# TC37XPD register map
Vendor: Infineon; Series: ATVMC; File version: 100
CPU: other r0p0, little endian, MPU, FPU, vendor SysTick, 4 interrupt priority bits
Registers are 32-bit, read-write, reset 0x0 unless marked. A register's access mark holds for its fields unless they carry their own. Offsets are from the block's base; [hi:lo] are bit positions; {n}, {i} and the like mark numbered series; 'fields as' and 'values as' point back to an identical list.

## ERAY0 (part 1 of 3) — ERAY
Base 0xF001C000
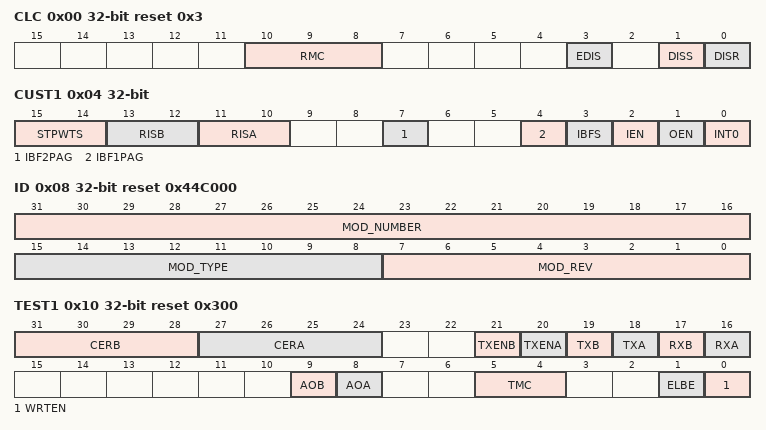
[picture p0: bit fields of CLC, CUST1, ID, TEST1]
0x00 CLC access per field reset 0x3 — Clock Control Register resetvalue={Application Reset:0x3}
  [10:8] RMC rw — Clock Divider in Run Mode RMC. This bit field is not affected by an application reset. This bit field only controls the kernel clock f CLC ERAY and not the sampling clock f SCLK .
  [3] EDIS rw — External Sleep Mode Request Disable Bit EDIS. Used to control module 8217 s sleep mode. If this bit is cleared the kernel clock f CLC ERAY and the sampling clock f SCLK are disabled during System Sleep Mode.
  [1] DISS ro — Module Disable Status Bit DISS. Bit indicates the current status of the module.
  [0] DISR rw — Module Disable Request Bit DISR. Used for enable disable control of the module. This bit disables the kernel clocks f CLC ERAY and the sampling clock f SCLK .
0x04 CUST1 access per field — Busy and Input Buffer Control Register resetvalue={Application Reset:0x0}
  [15:14] STPWTS rw — Stop Watch Trigger Input Select STPWTS
  [13:12] RISB rw — Receive Input Select Channel B RISB
  [11:10] RISA rw — Receive Input Select Channel A RISA
  [7] IBF2PAG rw — Input Buffer 2 Page Select Register IBF2PAG. This control bit selects if the upper page or lower page of Input Buffer 2 IBF2 currently active. Write is only possible if Input Buffer RAM 2 is currently accessible by the host via CIF and therefore IBFS cleared.
  [4] IBF1PAG rw — Input Buffer 1 Page Select Register IBF1PAG. This control bit selects if the upper page or lower page of Input Buffer 1 IBF1 currently active. Write is only possible if Input Buffer RAM 1 is currently accessible by the host via CIF and therefore IBFS set.
  [3] IBFS ro — Input Buffer Status Register IBFS. This status bit eray mhd signal ifb ifb1 2n indicates which of the two Input Buffer RAMs IBF is accessible by the host via CIF as Input Buffer. The other non accessible buffer RAM is currently used as shadow buffer RAM by the ERAY message handler and therefore not accessible by the host. After reset it is set by hardware.
  [2] IEN rw — Enable auto delay scheme for Input Buffer Control Register IBCR IEN. This control bit controls the auto delay scheme for Input Buffer Control Register IBCR read accesses.
  [1] OEN rw — Enable auto delay scheme for Output Buffer Control Register OBCR OEN. This control bit controls the delay scheme for Output Buffer Control Register OBCR read accesses.
  [0] INT0 rw — CIF Timeout Service Request Status INT0. INT0 will be set if a timeout has occurred during the auto delay scheme and must be reset by writing zero to INT0. Software can also set this bit field. In case hardware sets INT0 and at the same point of time software clears INT0 INT0 is cleared.
0x08 ID ro reset 0x44C000 (reset mask 0xFFFFFF00) — Module Identification Register resetvalue={Application Reset:0x44C000}
  [31:16] MOD_NUMBER — Module Number Value MOD NUMBER. This bit field defines a module identification number. For the E Ray module the module identification number is 44 H .
  [15:8] MOD_TYPE — Module Type MOD TYPE. The value of this bit field is C0 H . It defines the module as a 32 bit module.
  [7:0] MOD_REV — Module Revision Number MOD REV. MOD REV defines the module revision number. The value of a module revision starts with 01 H first revision .
0x0C CUST3 — Customer Interface Timeout Counter Register resetvalue={Application Reset:0x0}
  [31:0] TO — CIF Timeout Reload Value TO. The 32 bit down counter reload start up value must be setup for the automatic delay scheme.
0x10 TEST1 access per field reset 0x300 — Test Register 1 resetvalue={Application Reset:0x300}
  [31:28] CERB ro — Coding Error Report Channel B CERB. Set when a coding error is detected on channel B. Reset to zero when register TEST1 is read or written. Once the CERB is set it will remain unchanged until the Host accesses the TEST1 register. Other combinations are reserved.
  [27:24] CERA ro — Coding Error Report Channel A CERA. Set when a coding error is detected on channel A. Reset to zero when register TEST1 is read or written. Once the CERA is set it will remain unchanged until the Host accesses the TEST1 register. Other combinations are reserved.
  [21] TXENB rw — Read or Write to Channel B Transmit Enable Pin TXENB. A write to this bit field sets the TXENB to corresponding logic state. A read from this bit field shows the current logic state of TXENB.
  [20] TXENA rw — Read or Write to Channel A Transmit Enable Pin TXENA. A write to this bit field sets the TXENA to corresponding logic state. A read from this bit field shows the current logic state of TXENA.
  [19] TXB rw — Read or Write to Channel B Transmit Pin TXB. A write to this bit field sets the TXDB to corresponding logic state. A read from this bit field shows the current logic state of TXDB.
  [18] TXA rw — Read or Write to Channel A Transmit Pin TXA. A write to this bit field sets the TXDA to corresponding logic state. A read from this bit field shows the current logic state of TXDA.
  [17] RXB ro — Read Channel B Receive Pin RXB. This bit field shows the current logic state of RXDB.
  [16] RXA ro — Read Channel A Receive Pin RXA. This bit field shows the current logic state of RXDA.
  [9] AOB ro — Activity on B AOB. The channel idle condition is specified in the FlexRay 8482 protocol spec v2.1 chapter 3 BITSTRB process zChannelIdle .
  [8] AOA ro — Activity on A AOA. The channel idle condition is specified in the FlexRay protocol spec v2.1 chapter 3 BITSTRB process zChannelIdle .
  [5:4] TMC rw — Test Multiplexer Control TMC
  [1] ELBE rw — External Loop Back Enable ELBE. There are two possibilities to perform a loop back test. External loop back via physical layer or internal loop back for in system self test default . In case of an internal loop back pins TXENA and TXENB are in their inactive state pins TXDA and TXDB are set to HIGH pins RXDA and RXDB are not evaluated. Bit ELBE is evaluated only when POC is in loop back mode and test multiplexer control is in non multiplexed mode TMC 00.
  [0] WRTEN rw — Write Test Register Enable WRTEN. Enables write access to the test registers. To set the bit from 0 to 1 the test mode key has to be written as defined on 8220 Lock Register 8221 . The unlock sequence is not required when TEST1.WRTEN is kept at 1 while other bits of the register are changed. The bit can be reset to 0 at any time.
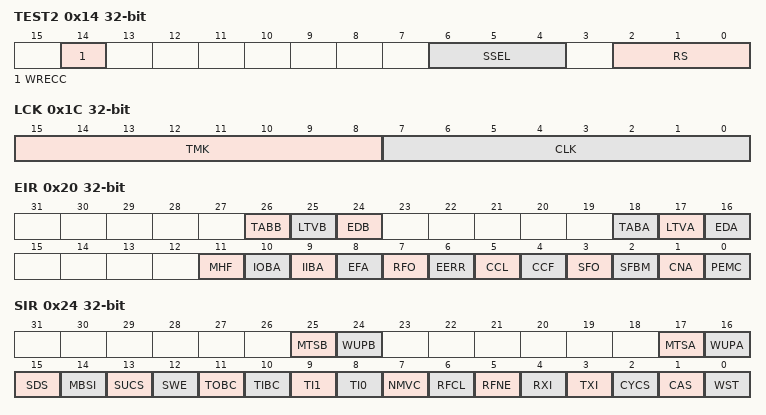
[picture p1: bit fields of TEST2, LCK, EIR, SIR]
0x14 TEST2 — Test Register 2 resetvalue={Application Reset:0x0}
  [14] WRECC — Write ECC Data Enable WRECC. Content of ECCW is transferred to the RAM Test mode must be entered. See 8220 Test Register 1 8221
  [6:4] SSEL — Segment Select SSEL. To enable access to the complete Message RAM 8192 byte addresses the Message RAM is segmented.
  [2:0] RS — RAM Select RS. In RAM Test mode the RAM blocks selected by RS are mapped to module address 0000 160 0400 H to 0000 160 07FF H 1024 byte addresses .
0x1C LCK wo — Lock Register resetvalue={Application Reset:0x0}
  [15:8] TMK — Test Mode Key TMK. To set bit TEST1.WRTEN the write operation has to be directly preceded by two consecutive write accesses to the Test Mode Key. If the write sequence is interrupted by other write accesses between the second write to the Test Mode Key and the write access to the Test1 register bit TEST1.WRTEN is not set to 1 and the sequence has to be repeated. First write LCK.TMK 75 H 0111 0101 B Second write LCK.TMK 8A H 1000 1010 B Second write TEST1.WRTEN 1 Returns 0 if read
  [7:0] CLK — Configuration Lock Key CLK. To leave CONFIG state by writing to SUCC1.CMD commands READY MONITOR MODE ATM LOOP BACK in the SUC Configuration Register 1 the write operation has to be directly preceded by two consecutive write accesses to the Configuration Lock Key unlock sequence . If the write sequence below is interrupted by other write accesses between the second write to the Configuration Lock Key and the write access to the SUCC1 register the Communication Controller remains in CONFIG state and the sequence has to be repeated. First write LCK.CLK CE H 1100 1110 B Second write LCK.CLK 31 H 0011 0001 B Third write SUCC1.CMD Returns 0 if read
0x20 EIR access per field — Error Service Request Select Register resetvalue={Application Reset:0x0}
  [26] TABB rw — Transmission Across Boundary Channel B TABB. The flag signals to the Host that a transmission across a slot boundary occurred for channel B. This flag is cleared by writing a 1.
  [25] LTVB rw — Latest Transmit Violation Channel B LTVB. The flag signals a latest transmit violation on channel B to the Host. This flag is cleared by writing a 1.
  [24] EDB rw — Error Detected on Channel B EDB. This bit is set whenever one of the flags ACS.SEDB ACS.CEDB ACS.CIB ACS.SBVB changes from 0 to 1. This flag is cleared by writing a 1.
  [18] TABA rw — Transmission Across Boundary Channel A TABA. The flag signals to the Host that a transmission across a slot boundary occurred for channel A. This flag is cleared by writing a 1.
  [17] LTVA rw — Latest Transmit Violation Channel A LTVA. The flag signals a latest transmit violation on channel A to the Host. This flag is cleared by writing a 1.
  [16] EDA rw — Error Detected on Channel A EDA. This bit is set whenever one of the flags ACS.SEDA ACS.CEDA ACS.CIA ACS.SBVA changes from 0 to 1. This flag is cleared by writing a 1.
  [11] MHF rw — Message Handler Constraints Flag MHF. The flag signals a Message Handler constraints violation condition. It is set whenever one of the flags MHDF.SNUA MHDF.SNUB MHDF.FNFA MHDF.FNFB MHDF.TBFA MHDF.TBFB MHDF.TNSA MHDF.TNSB MHDF.WAHP changes from 0 to 1.
  [10] IOBA rw — Illegal Output Buffer Access IOBA. This flag is set by the Communication Controller when the Host requests the transfer of a Message Buffer from the Message RAM to the Output Buffer while OBCR.OBSYS is set to 1.
  [9] IIBA rw — Illegal Input Buffer Access IIBA. This flag is set by the Communication Controller when the Host wants to modify a Message Buffer via Input Buffer while the Communication Controller is not in 8220 CONFIG 8221 or 8220 DEFAULT CONFIG 8221 state and one of the following conditions applies The Host writes to the Input Buffer Command Request register to modify the Header Section of Message Buffer 0 1 if configured for transmission in key slot Header Section of static Message Buffers with buffer number lt MRC.FDB while MRC.SEC 01 B Header Section of any static or dynamic Message Buffer while MRC.SEC 1x B Header and or Data Section of any message buffer belonging to the receive FIFO The Host writes to any register of the Input Buffer while IBCR.IBSYS is set.
  [8] EFA rw — Empty FIFO Access EFA. This flag is set by the Communication Controller when the Host requests the transfer of a message from the receive FIFO via Output Buffer while the receive FIFO is empty.
  [7] RFO ro — Receive FIFO Overrun RFO. The flag is set by the Communication Controller when a receive FIFO overrun is detected. When a receive FIFO overrun occurs the oldest message is overwritten with the actual received message. The actual state of the FIFO is monitored in register FSR.
  [6] EERR ro — ECC Error EERR. The flag signals an ECC error to the Host. It is set whenever one of the flags MHDS.EIBF MHDS.EOBF MHDS.EMR MHDS.ETBF1 MHDS.ETBF2 changes from 0 to 1. See also 8220 Message Handler Status 8221 . This bit must be cleared at initialization of the module
  [5] CCL rw — CHI Command Locked CCL. The flag signals that the write access to the CHI command vector SUCC1.CMD was not successful because the execution of the previous CHI command has not yet completed. In this case bit EIR.CNA is also set to 1. This flag is cleared by writing a 1.
  [4] CCF rw — Clock Correction Failure CCF. This flag is set at the end of the cycle whenever one of the following errors occurred Missing offset and or rate correction Clock Correction limit reached The clock correction status is monitored in registers CCEV and SFS. A failure may occur during startup therefore bit CCF should be cleared by the Host after the Communication Controller entered 8220 NORMAL ACTIVE 8221 state. This flag is cleared by writing a 1.
  [3] SFO rw — SYNC Frame Overflow SFO. Set when either the number of SYNC Frames received during the last communication cycle or the total number of SYNC Frames received during the last double cycle exceeds the maximum number of SYNC Frames as defined by GTUC02.SNM in the GTU Configuration Register 160 2. This flag is cleared by writing a 1.
  [2] SFBM rw — SYNC Frames Below Minimum SFBM. This flag signals that the number of SYNC Frames received during the last communication cycle was below the limit required by the FlexRay 8482 protocol. May be set during startup and therefore should be cleared by the Host after the Communication Controller entered 8220 NORMAL ACTIVE 8221 state. This flag is cleared by writing a 1.
  [1] CNA rw — Command Not Accepted CNA. The flag signals that the write access to the CHI command vector SUCC1.CMD in the SUC Configuration Register 1 was not successful because the requested command was not valid in the actual POC state or because the CHI command was locked CCL 1 . This flag is cleared by writing a 1.
  [0] PEMC rw — POC Error Mode Changed PEMC. This flag is set whenever the error mode signalled by CCEV.ERRM in the Communication Controller Error Vector register has changed. This flag is cleared by writing a 1.
0x24 SIR access per field — Status Service Request Register resetvalue={Application Reset:0x0}
  [25] MTSB rw — MTS Received on Channel B MTSB. Media Access Test symbol received on channel B during the proceeding symbol window. Updated by the Communication Controller for each channel at the end of the symbol window. This flag is cleared by writing a 1.
  [24] WUPB rw — Wakeup Pattern Channel B WUPB. This flag is set by the Communication Controller when a wakeup pattern was received on channel B. Only set when the Communication Controller is in 8220 WAKEUP 8221 8220 READY 8221 or 8220 STARTUP 8221 state or when in Monitor mode. This flag is cleared by writing a 1.
  [17] MTSA rw — MTS Received on Channel A vSS ValidMTSA MTSA. Media Access Test symbol received on channel A during the proceeding symbol window. Updated by the Communication Controller for each channel at the end of the symbol window. This flag is cleared by writing a 1.
  [16] WUPA rw — Wakeup Pattern Channel A WUPA. This flag is set by the Communication Controller when a wakeup pattern was received on channel A. Only set when the Communication Controller is in WAKEUP READY or STARTUP state or when in Monitor mode. This flag is cleared by writing a 1.
  [15] SDS rw — Start of Dynamic Segment SDS. This flag is set by the Communication Controller when the dynamic segment starts.
  [14] MBSI rw — Message Buffer Status Service Request MBSI. This flag is set by the Communication Controller when the Message Buffer status MBS has changed and if bit RDHS1.MBI of that Message Buffer is set. This flag is cleared by writing a 1.
  [13] SUCS rw — Startup Completed Successfully SUCS. This flag is set whenever a startup completed successfully and the Communication Controller entered NORMAL ACTIVE state. This flag is cleared by writing a 1.
  [12] SWE rw — Stop Watch Event SWE. This flag is set after a stop watch activation when the current cycle counter and Macrotick value are stored in the Stop Watch Register 1 STPW1 . This flag is cleared by writing a 1.
  [11] TOBC rw — Transfer Output Buffer Completed TOBC. This flag is set whenever a transfer from Message RAM to the Output Buffer has completed and bit OBCR.OBSYS in the Output Buffer Command Request register has been reset by the Message Handler. This flag is cleared by writing a 1.
  [10] TIBC rw — Transfer Input Buffer Completed TIBC. This flag is set whenever a transfer from Input Buffer to the Message RAM has completed and bit IBCR.IBSYS in the Input Buffer Command Request register has been reset by the Message Handler. This flag is cleared by writing a 1.
  [9] TI1 rw — Timer Service Request 1 TI1. This flag is set whenever the conditions programmed in the Timer Service Request 1 Configuration Register T1C are met. A Timer Service Request 1 is also signalled by TINT1SRC. This flag is cleared by writing a 1.
  [8] TI0 rw — Timer Service Request 0 TI0. This flag is set whenever timer 0 matches the conditions configured in the Timer Service Request 0 Configuration Register T0C. A Timer Service Request 0 is also signalled by TINT0SRC. This flag is cleared by writing a 1.
  [7] NMVC rw — Network Management Vector Changed NMVC. This service request flag signals a change in the Network Management Vector visible to the Host. This flag is cleared by writing a 1.
  [6] RFCL ro — Receive FIFO Critical Level RFCL. This flag is set when a valid receive FIFO fill level FSR.RFFL is equal or greater than the critical level as configured by FCL.CL.
  [5] RFNE ro — Receive FIFO Not Empty RFNE. This flag is set by the Communication Controller when a received valid Frame was stored into the empty receive FIFO.m The actual state of the receive FIFO is monitored in register FSR
  [4] RXI rw — Receive Service Request RXI. This flag is set by the Communication Controller whenever the set condition of a Message Buffer ND flag is fulfilled and if bit WRHS1.MBI of that Message Buffer is set to 1. This flag is cleared by writing a 1.
  [3] TXI rw — Transmit Service Request TXI. This flag is set by the Communication Controller at the end of Frame transmission if bit WRHS1.MBI in the respective Message Buffer is set. This flag is cleared by writing a 1.
  [2] CYCS rw — Cycle Start Service Request CYCS. This flag is set by the Communication Controller when a communication cycle starts This flag is cleared by writing a 1.
  [1] CAS rw — Collision Avoidance Symbol CAS. This flag is set by the Communication Controller during STARTUP state when a CAS or potential CAS was received. This flag is cleared by writing a 1.
  [0] WST rw — Wakeup Status WST. This flag is set when the wakeup status vector CCSV.WSV in the Communication Controller Status Vector register changes to a value other than UNDEFINED. This flag is cleared by writing a 1.
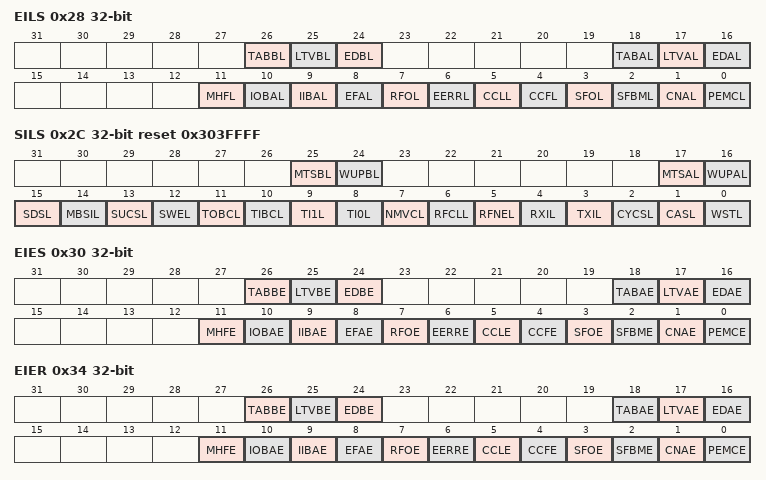
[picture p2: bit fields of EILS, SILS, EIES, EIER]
0x28 EILS — Error Service Request Line Select resetvalue={Application Reset:0x0}
  [26] TABBL — Transmission Across Boundary Channel B Service Request Line TABBL
  [25] LTVBL — Latest Transmit Violation Channel B Service Request Line LTVBL
  [24] EDBL — Error Detected on Channel B Service Request Line EDBL
  [18] TABAL — Transmission Across Boundary Channel A Service Request Line TABAL
  [17] LTVAL — Latest Transmit Violation Channel A Service Request Line LTVAL
  [16] EDAL — Error Detected on Channel A Service Request Line EDAL
  [11] MHFL — Message Handler Constrains Flag Service Request Line MHFL
  [10] IOBAL — Illegal Output Buffer Access Service Request Line IOBAL
  [9] IIBAL — Illegal Input Buffer Access Service Request Line IIBAL
  [8] EFAL — Empty FIFO Access Service Request Line EFAL
  [7] RFOL — Receive FIFO Overrun Service Request Line RFOL
  [6] EERRL — ECC Error Service Request Line EERRL
  [5] CCLL — CHI Command Locked Service Request Line CCLL
  [4] CCFL — Clock Correction Failure Service Request Line CCFL
  [3] SFOL — SYNC Frame Overflow Service Request Line SFOL
  [2] SFBML — SYNC Frames Below Minimum Service Request Line SFBML
  [1] CNAL — Command Not Accepted Service Request Line CNAL
  [0] PEMCL — POC Error Mode Changed Service Request Line PEMCL
0x2C SILS reset 0x303FFFF — Status Service Request Line Select resetvalue={Application Reset:0x303FFFF}
  [25] MTSBL — Media Access Test Symbol Channel B Service Request Line MTSBL
  [24] WUPBL — Wakeup Pattern Channel B Service Request Line WUPBL
  [17] MTSAL — Media Access Test Symbol Channel A Service Request Line MTSAL
  [16] WUPAL — Wakeup Pattern Channel A Service Request Line WUPAL
  [15] SDSL — Start of Dynamic Segment Service Request Line SDSL
  [14] MBSIL — Message Buffer Status Service Request Line MBSIL
  [13] SUCSL — Startup Completed Successfully Service Request Line SUCSL
  [12] SWEL — Stop Watch Event Service Request Line SWEL
  [11] TOBCL — Transfer Output Buffer Completed Service Request Line TOBCL
  [10] TIBCL — Transfer Input Buffer Completed Service Request Line TIBCL
  [9] TI1L — Timer Service Request 1 Line TI1L
  [8] TI0L — Timer Service Request 0 Line TI0L
  [7] NMVCL — Network Management Vector Changed Service Request Line NMVCL
  [6] RFCLL — Receive FIFO Critical Level Service Request Line RFCLL
  [5] RFNEL — Receive FIFO Not Empty Service Request Line RFNEL
  [4] RXIL — Receive Service Request Line RXIL
  [3] TXIL — Transmit Service Request Line TXIL
  [2] CYCSL — Cycle Start Service Request Line CYCSL
  [1] CASL — Collision Avoidance Symbol Service Request Line CASL
  [0] WSTL — Wakeup Status Service Request Line WSTL
0x30 EIES — Error Service Request Enable Set resetvalue={Application Reset:0x0}
  [26] TABBE — Transmission Across Boundary Channel B Service Request Enable TABBE
  [25] LTVBE — Latest Transmit Violation Channel B Service Request Enable LTVBE
  [24] EDBE — Error Detected on Channel B Service Request Enable EDBE
  [18] TABAE — Transmission Across Boundary Channel A Service Request Enable TABAE
  [17] LTVAE — Latest Transmit Violation Channel A Service Request Enable LTVAE
  [16] EDAE — Error Detected on Channel A Service Request Enable EDAE
  [11] MHFE — Message Handler Constraints Flag Service Request Enable MHFE
  [10] IOBAE — Illegal Output Buffer Access Service Request Enable IOBAE
  [9] IIBAE — Illegal Input Buffer Access Service Request Enable IIBAE
  [8] EFAE — Empty FIFO Access Service Request Enable EFAE
  [7] RFOE — Receive FIFO Overrun Service Request Enable RFOE
  [6] EERRE — ECC Error Service Request Enable EERRE
  [5] CCLE — CHI Command Locked Service Request Enable CCLE
  [4] CCFE — Clock Correction Failure Service Request Enable CCFE
  [3] SFOE — SYNC Frame Overflow Service Request Enable SFOE
  [2] SFBME — SYNC Frames Below Minimum Service Request Enable SFBME
  [1] CNAE — Command Not Accepted Service Request Enable CNAE
  [0] PEMCE — POC Error Mode Changed Service Request Enable PEMCE
0x34 EIER — Error Service Request Enable Reset resetvalue={Application Reset:0x0}
  fields as EIES
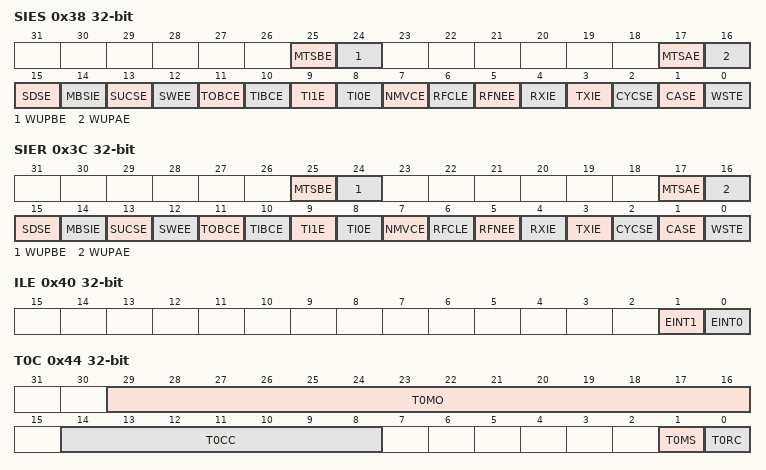
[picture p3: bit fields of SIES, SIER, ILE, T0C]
0x38 SIES — Status Service Request Enable Set resetvalue={Application Reset:0x0}
  [25] MTSBE — Media Access Test Symbol Channel B Service Request Enable MTSBE
  [24] WUPBE — Wakeup Pattern Channel B Service Request Enable WUPBE
  [17] MTSAE — Media Access Test Symbol Channel A Service Request Enable MTSAE
  [16] WUPAE — Wakeup Pattern Channel A Service Request Enable WUPAE
  [15] SDSE — Start of Dynamic Segment Service Request Enable SDSE
  [14] MBSIE — Message Buffer Status Service Request Enable MBSIE
  [13] SUCSE — Startup Completed Successfully Service Request Enable SUCSE
  [12] SWEE — Stop Watch Event Service Request Enable SWEE
  [11] TOBCE — Transfer Output Buffer Completed Service Request Enable TOBCE
  [10] TIBCE — Transfer Input Buffer Completed Service Request Enable TIBCE
  [9] TI1E — Timer Service Request 1 Enable TI1E
  [8] TI0E — Timer Service Request 0 Enable TI0E
  [7] NMVCE — Network Management Vector Changed Service Request Enable NMVCE
  [6] RFCLE — Receive FIFO Critical Level Service Request Enable RFCLE
  [5] RFNEE — Receive FIFO Not Empty Service Request Enable RFNEE
  [4] RXIE — Receive Service Request Enable RXIE
  [3] TXIE — Transmit Service Request Enable TXIE
  [2] CYCSE — Cycle Start Service Request Enable CYCSE
  [1] CASE — Collision Avoidance Symbol Service Request Enable CASE
  [0] WSTE — Wakeup Status Service Request Enable WSTE
0x3C SIER — Status Service Request Enable Reset resetvalue={Application Reset:0x0}
  fields as SIES
0x40 ILE — Service Request Line Enable resetvalue={Application Reset:0x0}
  [1] EINT1 — Enable Service Request Line 1 INT1SRC EINT1
  [0] EINT0 — Enable Service Request Line 0 INT0SRC EINT0
0x44 T0C — Timer 0 Configuration resetvalue={Application Reset:0x0}
  [29:16] T0MO — Timer 0 Macrotick Offset T0MO. Configures the Macrotick offset from the beginning of the cycle where the service request is to occur. The Timer 0 Service Request occurs at this offset for each cycle of the cycle set.
  [14:8] T0CC — Timer 0 Cycle Code T0CC. The 7 bit timer 0 cycle code determines the cycle set used for generation of the timer 0 service request. For details about the configuration of the cycle code see 8220 Cycle Counter Filtering 8221 .
  [1] T0MS — Timer 0 Mode Select T0MS
  [0] T0RC — Timer 0 Run Control T0RC
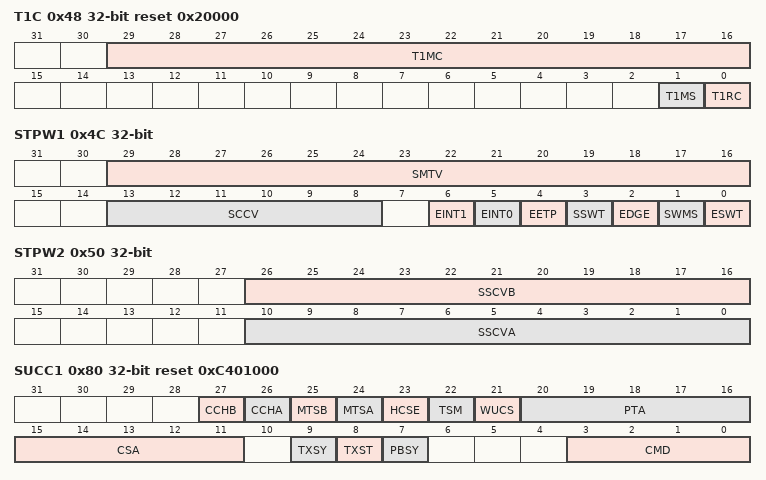
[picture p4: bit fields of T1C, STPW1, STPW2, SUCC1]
0x48 T1C reset 0x20000 — Timer 1 Configuration resetvalue={Application Reset:0x20000}
  [29:16] T1MC — Timer 1 Macrotick Count T1MC. When the configured Macrotick count is reached the timer 1 service request is generated. Valid values are 2 H 3FFF H Macroticks in continuous mode 1 H 3FFF H Macroticks in single shot mode
  [1] T1MS — Timer 1 Mode Select T1MS
  [0] T1RC — Timer 1 Run Control T1RC
0x4C STPW1 access per field — Stop Watch Register 1 resetvalue={Application Reset:0x0}
  [29:16] SMTV ro — Stopped Macrotick Value SMTV. State of the Macrotick counter when the stop watch event occurred. Valid values are 0 3F H Valid Values
  [13:8] SCCV ro — Stopped Cycle Counter Value SCCV. State of the cycle counter when the stop watch event occurred. Valid values are 0 3F H Valid Values
  [6] EINT1 rw — Enable Service Request 1 Trigger EINT1. Enables stop watch trigger by service request 1 event if ESWT 1.
  [5] EINT0 rw — Enable Service Request 0 Trigger EINT0. Enables stop watch trigger by service request 0 event if ESWT 1.
  [4] EETP rw — Enable External Trigger Pin EETP. Enables stop watch trigger event via signal STPW eray stpwt if ESWT 1.
  [3] SSWT rw — Software Stop Watch Trigger SSWT. When the Host writes this bit to 1 the stop watch is activated. After the actual cycle counter and Macrotick value are stored in the Stop Watch register this bit is reset to 0. The bit is only writeable while ESWT 0.
  [2] EDGE rw — Stop Watch Trigger Edge Select EDGE
  [1] SWMS rw — Stop Watch Mode Select SWMS. It is not possible to change the Stop Watch Mode during enabled stop watch trigger STPW1.ESWT
  [0] ESWT rw — Enable Stop Watch Trigger ESWT. If enabled an edge on input STPW pin eray stpwt if embedded eray stpwt0 eray stpwt1 eray stpwt2 or eray stpwt3 or a service request 0 or 1 event rising edge on signal INT0SR or INT1SR eray int0 or eray int 1 activates the stop watch. In single shot mode this bit is reset to 0 after the actual cycle counter and Macrotick value are stored in the Stop Watch register.
0x50 STPW2 ro — Stop Watch Register 2 resetvalue={Application Reset:0x0}
  [26:16] SSCVB — Stop Watch Captured Slot Counter Value Channel B SSCVB. State of the slot counter for channel B when the stop watch event occurred. Valid values are 0 to 2047 0 H to 7FF H .
  [10:0] SSCVA — Stop Watch Captured Slot Counter Value Channel A SSCVA. State of the slot counter for channel A when the stop watch event occurred. Valid values are 0 to 2047 0 H to 7FF H .
0x80 SUCC1 access per field reset 0xC401000 — SUC Configuration Register 1 resetvalue={Application Reset:0x0C401000}
  [27] CCHB rw — Connected to Channel B pChannels CCHB. Configures whether the node is connected to channel B.
  [26] CCHA rw — Connected to Channel A pChannels CCHA. Configures whether the node is connected to channel A.
  [25] MTSB rw — Select Channel B for MTS Transmission MTSB. The bit selects channel B for MTS symbol transmission. The flag is reset by default and may be modified only in 8220 DEFAULT CONFIG 8221 or 8220 CONFIG 8221 state.
  [24] MTSA rw — Select Channel A for MTS Transmission MTSA. The bit selects channel A for MTS symbol transmission. The flag is reset by default and may be modified only in 8220 DEFAULT CONFIG 8221 or 8220 CONFIG 8221 state.
  [23] HCSE rw — Halt due to Clock Sync Error pAllowHaltDueToClock HCSE. Controls the transition to 8220 HALT 8221 state due to a clock synchronization error. The bit can be modified in 8220 DEFAULT CONFIG 8221 or 8220 CONFIG 8221 state only.
  [22] TSM rw — Transmission Slot Mode pSingleSlotEnabled TSM. Selects the initial transmission slot mode. In SINGLE slot mode the Communication Controller may only transmit in the preconfigured key slot. The key slot ID is configured in the Header Section of Message Buffer 0 respectively Message Buffers 0 and 1 depending on bit MRC.SPLM. In case SUCC1.TSM 1 Message Buffer 0 respectively Message Buffers 0 1 can be re configured in 8220 DEFAULT CONFIG 8221 or 8220 CONFIG 8221 state only. In ALL slot mode the Communication Controller may transmit in all slots. The bit can be written in 8220 DEFAULT CONFIG 8221 or 8220 CONFIG 8221 state only. The communication controller changes to ALL slot mode when the Host successfully applied the ALL SLOTS command by writing SUCC1.CMD 160 160 0101 B in POC states 8220 NORMAL ACTIVE 8221 or 8220 NORMAL PASSIVE 8221 . The actual slot mode is monitored by CCSV.SLM.
  [21] WUCS rw — Wakeup Channel Select pWakeupChannel WUCS. With this bit the Host selects the channel on which the Communication Controller sends the Wakeup pattern. The Communication Controller ignores any attempt to change the status of this bit when not in 8220 DEFAULT CONFIG 8221 or 8220 CONFIG 8221 state.
  [20:16] PTA rw — Passive to Active pAllowPassiveToActive PTA. Defines the number of consecutive even odd cycle pairs that must have valid clock correction terms before the Communication Controller is allowed to transit from 8220 NORMAL PASSIVE 8221 to 8220 NORMAL ACTIVE 8221 state. If set to 00000 B the Communication Controller is not allowed to transit from 8220 NORMAL PASSIVE 8221 to 8220 NORMAL ACTIVE 8221 state. It can be modified in 8220 DEFAULT CONFIG 8221 or 8220 CONFIG 8221 state only. Valid values are 0 to 31 even odd cycle pairs.
  [15:11] CSA rw — Cold Start Attempts gColdStartAttempts CSA. Configures the maximum number of attempts that a cold starting node is permitted to try to start up the network without receiving any valid response from another node. It can be modified in 8220 DEFAULT CONFIG 8221 or 8220 CONFIG 8221 state only. Must be identical in all nodes of a cluster. Valid values are 2 to 31.
  [9] TXSY rw — Transmit SYNC Frame in Key Slot pKeySlotUsedForSync TXSY. Defines whether the key slot is used to transmit SYNC Frames. The bit can be modified in 8220 DEFAULT CONFIG 8221 or 8220 CONFIG 8221 state only. 1 2
  [8] TXST rw — Transmit Startup Frame in Key Slot pKeySlotUsedForStartup TXST. Defines whether the key slot is used to transmit startup Frames. The bit can be modified in 8220 DEFAULT CONFIG 8221 or 8220 CONFIG 8221 state only.
  [7] PBSY ro — POC Busy PBSY. Signals that the POC is busy and cannot accept a command from the Host. SUCC1.CMD is locked against write accesses. Set to 1 after hard reset during initialization of internal RAM blocks.
  [3:0] CMD rw — CHI Command Vector CMD. The host may write any CHI command at any time but certain commands are only enabled in specific POC states. A disabled command will not be executed the CHI command vector CMD will be reset to 0000 B 8220 COMMAND NOT ACCEPTED 8221 and flag EIR.CNA in the Error Service Request register will be set to 1. In case the previous CHI command has not yet completed EIR.CCL is set to 1 together with EIR.CNA the CHI command needs to be repeated. Except for HALT state POC state change command applied while the Communication Controller is already in the requested POC state will be ignored. Reading SUCC1.CMD shows whether the last CHI command was accepted. CCSV.POCS monitors the actual POC state. The reserved CHI commands code hardware test functions.
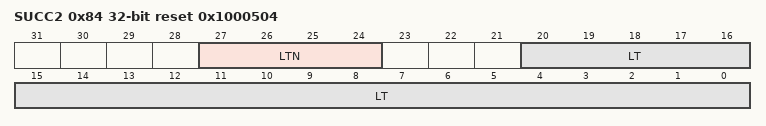
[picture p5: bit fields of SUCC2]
0x84 SUCC2 reset 0x1000504 — SUC Configuration Register 2 resetvalue={Application Reset:0x1000504}
  [27:24] LTN — Listen Time out Noise gListenNoise 1 LTN. Configures the upper limit for startup and wakeup listen timeout in the presence of noise expressed as a multiple of the cluster constant pdListenTimeout. The range of pdListenTimeout 2 to 16. LTN must be configured identical in all nodes of a cluster. This bit can be updated in quot DEFAULT CONFIG quot or quot CONFIG quot state only.
  [20:0] LT — Listen Timeout pdListenTimeout LT. Configures wakeup startup listen timeout in Microticks. The range for wakeup startup listen timeout pdListenTimeout is 1284 to 1283846 504 H to 139706 H Microticks
